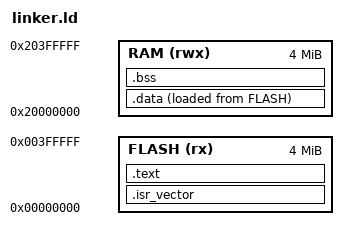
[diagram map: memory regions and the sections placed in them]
ENTRY(Reset_Handler)

MEMORY
{
  FLASH (rx)  : ORIGIN = 0x00000000, LENGTH = 4M
  RAM   (rwx) : ORIGIN = 0x20000000, LENGTH = 4M
}

_estack = ORIGIN(RAM) + LENGTH(RAM);

SECTIONS
{
  .isr_vector :
  {
    _vectors = .;
    . = ALIGN(4);
    KEEP(*(.isr_vector))
    KEEP(*(.vectors))
    . = ALIGN(4);
  } > FLASH

  .text :
  {
    . = ALIGN(4);
    *(.text)
    *(.text.*)
    *(.rodata)
    *(.rodata.*)
    . = ALIGN(4);
    _etext = .;
  } > FLASH

  _sidata = LOADADDR(.data);
  .data :
  {
    . = ALIGN(4);
    _sdata = .;
    *(.data)
    *(.data.*)
    . = ALIGN(4);
    _edata = .;
  } > RAM AT> FLASH

  .bss :
  {
    . = ALIGN(4);
    _sbss = .;
    *(.bss)
    *(.bss.*)
    *(COMMON)
    . = ALIGN(4);
    _ebss = .;
  } > RAM

  __RAM_segment_used_end__ = .;

  /DISCARD/ :
  {
    *(.ARM.exidx*)
    *(.ARM.extab*)
    *(.comment)
    *(.note.*)
  }
}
